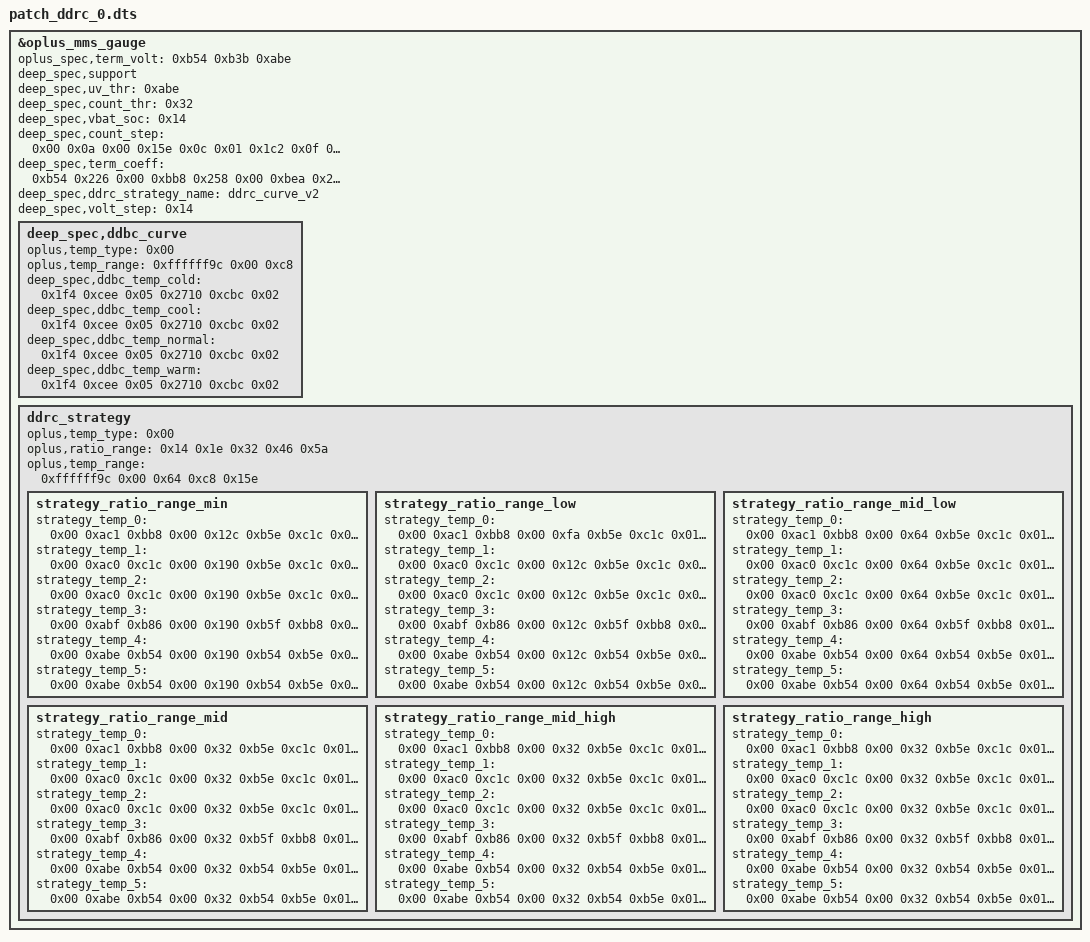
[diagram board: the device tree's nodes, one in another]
/dts-v1/;
/plugin/;

/ {
	fragment@0 {
		target = <&oplus_mms_gauge>;
		__overlay__ {
			oplus_spec,term_volt = <0xb54 0xb3b 0xabe>;
			deep_spec,support;
			deep_spec,uv_thr = <0xabe>;
			deep_spec,count_thr = <0x32>;
			deep_spec,vbat_soc = <0x14>;
			deep_spec,count_step = <0x00 0x0a 0x00 0x15e 0x0c 0x01 0x1c2 0x0f 0x02 0x212 0x14 0x03>;
			deep_spec,term_coeff = <0xb54 0x226 0x00 0xbb8 0x258 0x00 0xbea 0x2bc 0x00 0xc1c 0x2ee 0x00 0xc26 0x2ee 0x00 0xc4e 0x320 0x00 0xc58 0x320 0x00 0xc80 0x384 0x00 0xc8a 0x384 0x00 0xcbc 0x3e8 0x00>;
			deep_spec,ddrc_strategy_name = "ddrc_curve_v2";
			deep_spec,volt_step = <0x14>;
			
			deep_spec,ddbc_curve {
				oplus,temp_type = <0x00>;
				oplus,temp_range = <0xffffff9c 0x00 0xc8>;
				deep_spec,ddbc_temp_cold = <0x1f4 0xcee 0x05 0x2710 0xcbc 0x02>;
				deep_spec,ddbc_temp_cool = <0x1f4 0xcee 0x05 0x2710 0xcbc 0x02>;
				deep_spec,ddbc_temp_normal = <0x1f4 0xcee 0x05 0x2710 0xcbc 0x02>;
				deep_spec,ddbc_temp_warm = <0x1f4 0xcee 0x05 0x2710 0xcbc 0x02>;
			};
			
			ddrc_strategy {
				oplus,temp_type = <0x00>;
				oplus,ratio_range = <0x14 0x1e 0x32 0x46 0x5a>;
				oplus,temp_range = <0xffffff9c 0x00 0x64 0xc8 0x15e>;
				
				strategy_ratio_range_min {
					strategy_temp_0 = <0x00 0xac1 0xbb8 0x00 0x12c 0xb5e 0xc1c 0x01 0x2bc 0xbc2 0xc4e 0x02 0x44c 0xbf5 0xc58 0x03 0x5dc 0xc27 0xc8a 0x04 0x76c 0xc59 0xcbc 0x05>;
					strategy_temp_1 = <0x00 0xac0 0xc1c 0x00 0x190 0xb5e 0xc1c 0x01 0x384 0xbc2 0xc4e 0x02 0x578 0xbf5 0xc58 0x03 0x76c 0xc27 0xc8a 0x04 0x960 0xc59 0xcbc 0x05>;
					strategy_temp_2 = <0x00 0xac0 0xc1c 0x00 0x190 0xb5e 0xc1c 0x01 0x384 0xbc2 0xc4e 0x02 0x578 0xbf5 0xc58 0x03 0x76c 0xc27 0xc8a 0x04 0x960 0xc59 0xcbc 0x05>;
					strategy_temp_3 = <0x00 0xabf 0xb86 0x00 0x190 0xb5f 0xbb8 0x01 0x384 0xbb8 0xbc2 0x02 0x578 0xbf4 0xc26 0x03 0x76c 0xc27 0xc58 0x04 0x960 0xc58 0xc8a 0x05>;
					strategy_temp_4 = <0x00 0xabe 0xb54 0x00 0x190 0xb54 0xb5e 0x01 0x384 0xbb8 0xbc2 0x02 0x578 0xbea 0xbea 0x03 0x76c 0xc1c 0xc1c 0x04 0x960 0xc4e 0xc4e 0x05>;
					strategy_temp_5 = <0x00 0xabe 0xb54 0x00 0x190 0xb54 0xb5e 0x01 0x384 0xbb8 0xbc2 0x02 0x578 0xbea 0xbea 0x03 0x76c 0xc1c 0xc1c 0x04 0x960 0xc4e 0xc4e 0x05>;
				};
				
				strategy_ratio_range_low {
					strategy_temp_0 = <0x00 0xac1 0xbb8 0x00 0xfa 0xb5e 0xc1c 0x01 0x226 0xbc2 0xc4e 0x02 0x352 0xc26 0xc58 0x03 0x47e 0xc58 0xc8a 0x04 0x5aa 0xc8a 0xcbc 0x05>;
					strategy_temp_1 = <0x00 0xac0 0xc1c 0x00 0x12c 0xb5e 0xc1c 0x01 0x2bc 0xbc2 0xc4e 0x02 0x44c 0xbf5 0xc58 0x03 0x5dc 0xc27 0xc8a 0x04 0x76c 0xc59 0xcbc 0x05>;
					strategy_temp_2 = <0x00 0xac0 0xc1c 0x00 0x12c 0xb5e 0xc1c 0x01 0x2bc 0xbc2 0xc4e 0x02 0x44c 0xbf5 0xc58 0x03 0x5dc 0xc27 0xc8a 0x04 0x76c 0xc59 0xcbc 0x05>;
					strategy_temp_3 = <0x00 0xabf 0xb86 0x00 0x12c 0xb5f 0xbb8 0x01 0x2bc 0xbb8 0xbc2 0x02 0x44c 0xbf4 0xc26 0x03 0x5dc 0xc27 0xc58 0x04 0x76c 0xc58 0xc8a 0x05>;
					strategy_temp_4 = <0x00 0xabe 0xb54 0x00 0x12c 0xb54 0xb5e 0x01 0x2bc 0xbb8 0xbc2 0x02 0x44c 0xbea 0xbea 0x03 0x5dc 0xc1c 0xc1c 0x04 0x76c 0xc4e 0xc4e 0x05>;
					strategy_temp_5 = <0x00 0xabe 0xb54 0x00 0x12c 0xb54 0xb5e 0x01 0x2bc 0xbb8 0xbc2 0x02 0x44c 0xbea 0xbea 0x03 0x5dc 0xc1c 0xc1c 0x04 0x76c 0xc4e 0xc4e 0x05>;
				};
				
				strategy_ratio_range_mid_low {
					strategy_temp_0 = <0x00 0xac1 0xbb8 0x00 0x64 0xb5e 0xc1c 0x01 0xfa 0xbc2 0xc4e 0x02 0x190 0xc26 0xc58 0x03 0x226 0xc58 0xc8a 0x04 0x2bc 0xc8a 0xcbc 0x05>;
					strategy_temp_1 = <0x00 0xac0 0xc1c 0x00 0x64 0xb5e 0xc1c 0x01 0x12c 0xbc2 0xc4e 0x02 0x258 0xbf5 0xc58 0x03 0x384 0xc27 0xc8a 0x04 0x4b0 0xc59 0xcbc 0x05>;
					strategy_temp_2 = <0x00 0xac0 0xc1c 0x00 0x64 0xb5e 0xc1c 0x01 0x12c 0xbc2 0xc4e 0x02 0x258 0xbf5 0xc58 0x03 0x384 0xc27 0xc8a 0x04 0x4b0 0xc59 0xcbc 0x05>;
					strategy_temp_3 = <0x00 0xabf 0xb86 0x00 0x64 0xb5f 0xbb8 0x01 0x12c 0xbb8 0xbc2 0x02 0x258 0xbf4 0xc26 0x03 0x384 0xc27 0xc58 0x04 0x4b0 0xc58 0xc8a 0x05>;
					strategy_temp_4 = <0x00 0xabe 0xb54 0x00 0x64 0xb54 0xb5e 0x01 0x12c 0xbb8 0xbc2 0x02 0x258 0xbea 0xbea 0x03 0x384 0xc1c 0xc1c 0x04 0x4b0 0xc4e 0xc4e 0x05>;
					strategy_temp_5 = <0x00 0xabe 0xb54 0x00 0x64 0xb54 0xb5e 0x01 0x12c 0xbb8 0xbc2 0x02 0x258 0xbea 0xbea 0x03 0x384 0xc1c 0xc1c 0x04 0x4b0 0xc4e 0xc4e 0x05>;
				};
				
				strategy_ratio_range_mid {
					strategy_temp_0 = <0x00 0xac1 0xbb8 0x00 0x32 0xb5e 0xc1c 0x01 0x96 0xbc2 0xc4e 0x02 0x12c 0xc26 0xc58 0x03 0x1c2 0xc58 0xc8a 0x04 0x258 0xc8a 0xcbc 0x05>;
					strategy_temp_1 = <0x00 0xac0 0xc1c 0x00 0x32 0xb5e 0xc1c 0x01 0x96 0xbc2 0xc4e 0x02 0x15e 0xbf5 0xc58 0x03 0x226 0xc27 0xc8a 0x04 0x2ee 0xc59 0xcbc 0x05>;
					strategy_temp_2 = <0x00 0xac0 0xc1c 0x00 0x32 0xb5e 0xc1c 0x01 0x96 0xbc2 0xc4e 0x02 0x15e 0xbf5 0xc58 0x03 0x226 0xc27 0xc8a 0x04 0x2ee 0xc59 0xcbc 0x05>;
					strategy_temp_3 = <0x00 0xabf 0xb86 0x00 0x32 0xb5f 0xbb8 0x01 0x96 0xbb8 0xbc2 0x02 0x15e 0xbf4 0xc26 0x03 0x226 0xc27 0xc58 0x04 0x2ee 0xc58 0xc8a 0x05>;
					strategy_temp_4 = <0x00 0xabe 0xb54 0x00 0x32 0xb54 0xb5e 0x01 0x96 0xbb8 0xbc2 0x02 0x15e 0xbea 0xbea 0x03 0x226 0xc1c 0xc1c 0x04 0x2ee 0xc4e 0xc4e 0x05>;
					strategy_temp_5 = <0x00 0xabe 0xb54 0x00 0x32 0xb54 0xb5e 0x01 0x96 0xbb8 0xbc2 0x02 0x15e 0xbea 0xbea 0x03 0x226 0xc1c 0xc1c 0x04 0x2ee 0xc4e 0xc4e 0x05>;
				};
				
				strategy_ratio_range_mid_high {
					strategy_temp_0 = <0x00 0xac1 0xbb8 0x00 0x32 0xb5e 0xc1c 0x01 0x96 0xbc2 0xc4e 0x02 0xfa 0xc26 0xc58 0x03 0x15e 0xc58 0xc8a 0x04 0x1c2 0xc8a 0xcbc 0x05>;
					strategy_temp_1 = <0x00 0xac0 0xc1c 0x00 0x32 0xb5e 0xc1c 0x01 0x96 0xbc2 0xc4e 0x02 0xfa 0xbf5 0xc58 0x03 0x15e 0xc27 0xc8a 0x04 0x1c2 0xc59 0xcbc 0x05>;
					strategy_temp_2 = <0x00 0xac0 0xc1c 0x00 0x32 0xb5e 0xc1c 0x01 0x96 0xbc2 0xc4e 0x02 0xfa 0xbf5 0xc58 0x03 0x15e 0xc27 0xc8a 0x04 0x1c2 0xc59 0xcbc 0x05>;
					strategy_temp_3 = <0x00 0xabf 0xb86 0x00 0x32 0xb5f 0xbb8 0x01 0x96 0xbb8 0xbc2 0x02 0xfa 0xbf4 0xc26 0x03 0x15e 0xc27 0xc58 0x04 0x1c2 0xc58 0xc8a 0x05>;
					strategy_temp_4 = <0x00 0xabe 0xb54 0x00 0x32 0xb54 0xb5e 0x01 0x96 0xbb8 0xbc2 0x02 0xfa 0xc1c 0xc1c 0x03 0x15e 0xc4e 0xc4e 0x04 0x1c2 0xc80 0xc80 0x05>;
					strategy_temp_5 = <0x00 0xabe 0xb54 0x00 0x32 0xb54 0xb5e 0x01 0x96 0xbb8 0xbc2 0x02 0xfa 0xc1c 0xc1c 0x03 0x15e 0xc4e 0xc4e 0x04 0x1c2 0xc80 0xc80 0x05>;
				};
				
				strategy_ratio_range_high {
					strategy_temp_0 = <0x00 0xac1 0xbb8 0x00 0x32 0xb5e 0xc1c 0x01 0x96 0xbc2 0xc4e 0x02 0xfa 0xc26 0xc58 0x03 0x15e 0xc58 0xc8a 0x04 0x1c2 0xc8a 0xcbc 0x05>;
					strategy_temp_1 = <0x00 0xac0 0xc1c 0x00 0x32 0xb5e 0xc1c 0x01 0x96 0xbc2 0xc4e 0x02 0xfa 0xbf5 0xc58 0x03 0x15e 0xc27 0xc8a 0x04 0x1c2 0xc59 0xcbc 0x05>;
					strategy_temp_2 = <0x00 0xac0 0xc1c 0x00 0x32 0xb5e 0xc1c 0x01 0x96 0xbc2 0xc4e 0x02 0xfa 0xbf5 0xc58 0x03 0x15e 0xc27 0xc8a 0x04 0x1c2 0xc59 0xcbc 0x05>;
					strategy_temp_3 = <0x00 0xabf 0xb86 0x00 0x32 0xb5f 0xbb8 0x01 0x96 0xbb8 0xbc2 0x02 0xfa 0xbf4 0xc26 0x03 0x15e 0xc27 0xc58 0x04 0x1c2 0xc58 0xc8a 0x05>;
					strategy_temp_4 = <0x00 0xabe 0xb54 0x00 0x32 0xb54 0xb5e 0x01 0x96 0xbb8 0xbc2 0x02 0xfa 0xc1c 0xc1c 0x03 0x15e 0xc4e 0xc4e 0x04 0x1c2 0xc80 0xc80 0x05>;
					strategy_temp_5 = <0x00 0xabe 0xb54 0x00 0x32 0xb54 0xb5e 0x01 0x96 0xbb8 0xbc2 0x02 0xfa 0xc1c 0xc1c 0x03 0x15e 0xc4e 0xc4e 0x04 0x1c2 0xc80 0xc80 0x05>;
				};
			};
		};
	};
};
